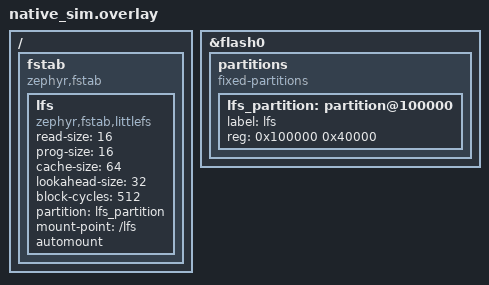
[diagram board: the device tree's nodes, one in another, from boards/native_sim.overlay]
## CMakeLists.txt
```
cmake_minimum_required(VERSION 3.20.0)

set(ZEPHYRDB_LOCAL_MODULE_DIR ${CMAKE_CURRENT_LIST_DIR}/modules/zephyrdb-local)
set(ZEPHYRDB_REPO_MODULE_DIR ${CMAKE_CURRENT_LIST_DIR}/../..)
if(EXISTS ${ZEPHYRDB_LOCAL_MODULE_DIR}/zephyr/module.yml OR
   EXISTS ${ZEPHYRDB_LOCAL_MODULE_DIR}/module.yml)
  list(APPEND EXTRA_ZEPHYR_MODULES ${ZEPHYRDB_LOCAL_MODULE_DIR})
elseif(EXISTS ${ZEPHYRDB_REPO_MODULE_DIR}/zephyr/module.yml OR
       EXISTS ${ZEPHYRDB_REPO_MODULE_DIR}/module.yml)
  list(APPEND EXTRA_ZEPHYR_MODULES ${ZEPHYRDB_REPO_MODULE_DIR})
else()
  message(FATAL_ERROR
    "shell_basic: zephyrdb module not found. Expected module.yml (or zephyr/module.yml) in one of: "
    "${ZEPHYRDB_LOCAL_MODULE_DIR} or ${ZEPHYRDB_REPO_MODULE_DIR}")
endif()

find_package(Zephyr REQUIRED HINTS $ENV{ZEPHYR_BASE})
project(zephyrdb_shell_basic)

target_sources(app PRIVATE src/main.c)
```

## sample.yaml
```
sample:
  name: ZephyrDB shell basic sample

common:
  tags:
    - zephyrdb
    - samples
    - shell
  integration_platforms:
    - native_sim

tests:
  zephyrdb.samples.shell_basic:
    harness: console
    harness_config:
      type: multi_line
      regex:
        - "shell_basic: KV selftest PASS"
        - "shell_basic: seeded kv/cfg, ts/temp, doc/sensors/s1"
        - "shell_basic: ZephyrDB shell ready"
    platform_allow:
      - native_sim
    timeout: 20
```

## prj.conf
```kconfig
CONFIG_CONSOLE=y
CONFIG_PRINTK=y
# The KV key index is sized by CONFIG_ZDB_KV_INDEX_MAX_ENTRIES and comes from
# this pool, as does every document field.
CONFIG_HEAP_MEM_POOL_SIZE=32768

CONFIG_SHELL=y
CONFIG_SHELL_BACKEND_SERIAL=y
# "zdb ts agg" and the f64 document commands print doubles.
CONFIG_CBPRINTF_FP_SUPPORT=y

CONFIG_FLASH=y
CONFIG_FLASH_MAP=y
CONFIG_FLASH_PAGE_LAYOUT=y
CONFIG_FLASH_SIMULATOR=y

CONFIG_FILE_SYSTEM=y
CONFIG_FILE_SYSTEM_LITTLEFS=y
CONFIG_FS_LITTLEFS_FMP_DEV=y
CONFIG_CRC=y

CONFIG_ZEPHYRDB=y
CONFIG_ZDB_SHELL=y
CONFIG_ZDB_STATS=y

CONFIG_ZDB_KV=y
CONFIG_ZDB_KV_BACKEND_ZMS=y
CONFIG_ZMS=y
CONFIG_NVS=n

CONFIG_ZDB_TS=y
CONFIG_ZDB_TS_BACKEND_LITTLEFS=y

CONFIG_ZDB_DOC=y
```

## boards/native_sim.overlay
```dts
/*
 * LittleFS partition and fstab automount for native_sim.
 *
 * The base native_sim DTS provides a 2 MB simulated flash with partitions
 * up to 0x100000.  This overlay adds a 256 KB LittleFS partition in the
 * remaining space and an fstab entry so the filesystem is mounted
 * automatically at boot.  The time-series and document models need it; KV
 * uses the stock storage_partition.
 */

&flash0 {
	partitions {
		compatible = "fixed-partitions";
		#address-cells = <1>;
		#size-cells = <1>;

		lfs_partition: partition@100000 {
			label = "lfs";
			reg = <0x100000 0x40000>;
		};
	};
};

/ {
	fstab {
		compatible = "zephyr,fstab";
		lfs: lfs {
			compatible = "zephyr,fstab,littlefs";
			read-size = <16>;
			prog-size = <16>;
			cache-size = <64>;
			lookahead-size = <32>;
			block-cycles = <512>;
			partition = <&lfs_partition>;
			mount-point = "/lfs";
			automount;
		};
	};
};
```

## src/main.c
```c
#include <zephyr/kernel.h>
#include <zephyr/sys/printk.h>
#include <zephyr/device.h>
#include <zephyr/drivers/flash.h>
#include <zephyr/kvss/zms.h>
#include <zephyr/storage/flash_map.h>

#include "zephyrdb.h"

static struct zms_fs g_zms;

static zdb_cfg_t g_cfg = {
	.kv_backend_fs = NULL,
	.lfs_mount_point = CONFIG_ZDB_LFS_MOUNT_POINT,
	.work_q = &k_sys_work_q,
};

ZDB_DEFINE_STATIC(g_db, g_cfg);

#define ZDB_ZMS_PARTITION storage_partition
#define ZDB_ZMS_PARTITION_DEVICE PARTITION_DEVICE(ZDB_ZMS_PARTITION)
#define ZDB_ZMS_PARTITION_OFFSET PARTITION_OFFSET(ZDB_ZMS_PARTITION)

static int shell_basic_init_zms(struct zms_fs *fs)
{
	struct flash_pages_info info;
	int rc;

	fs->flash_device = ZDB_ZMS_PARTITION_DEVICE;
	if (!device_is_ready(fs->flash_device)) {
		printk("shell_basic: storage device not ready\n");
		return -ENODEV;
	}

	fs->offset = ZDB_ZMS_PARTITION_OFFSET;
	rc = flash_get_page_info_by_offs(fs->flash_device, fs->offset, &info);
	if (rc != 0) {
		printk("shell_basic: flash page info failed rc=%d\n", rc);
		return rc;
	}

	fs->sector_size = info.size;
	fs->sector_count = 3U;

	rc = zms_mount(fs);
	if (rc != 0) {
		printk("shell_basic: zms mount failed rc=%d\n", rc);
		return rc;
	}

	return 0;
}

static int shell_basic_kv_selftest(zdb_t *db)
{
	zdb_kv_t kv;
	zdb_status_t rc;
	uint32_t write_value = 7U;
	uint32_t read_value = 0U;
	size_t out_len = 0U;

	rc = zdb_kv_open(db, "shell", &kv);
	if (rc != ZDB_OK) {
		printk("shell_basic: selftest kv_open rc=%d\n", (int)rc);
		return -EIO;
	}

	rc = zdb_kv_set(&kv, "smoke", &write_value, sizeof(write_value));
	if (rc != ZDB_OK) {
		printk("shell_basic: selftest kv_set rc=%d\n", (int)rc);
		(void)zdb_kv_close(&kv);
		return -EIO;
	}

	rc = zdb_kv_get(&kv, "smoke", &read_value, sizeof(read_value), &out_len);
	if ((rc != ZDB_OK) || (out_len != sizeof(read_value)) || (read_value != write_value)) {
		printk("shell_basic: selftest kv_get rc=%d len=%u val=%u\n", (int)rc,
		       (unsigned int)out_len, (unsigned int)read_value);
		(void)zdb_kv_close(&kv);
		return -EIO;
	}

	rc = zdb_kv_delete(&kv, "smoke");
	if (rc != ZDB_OK) {
		printk("shell_basic: selftest kv_delete rc=%d\n", (int)rc);
		(void)zdb_kv_close(&kv);
		return -EIO;
	}

	(void)zdb_kv_close(&kv);
	printk("shell_basic: KV selftest PASS\n");

	return 0;
}

/*
 * Seed one namespace, one stream, and one document so every command in the
 * tree has something to report the first time it is run.
 */
static void shell_basic_seed(zdb_t *db)
{
	static const zdb_ts_sample_i64_t samples[] = {
		{.ts_ms = 1000U, .value = 20},
		{.ts_ms = 1001U, .value = 21},
		{.ts_ms = 1002U, .value = 22},
	};
	zdb_kv_t kv;
	zdb_ts_t ts;
	zdb_doc_t doc;

	if (zdb_kv_open(db, "cfg", &kv) == ZDB_OK) {
		(void)zdb_kv_set_str(&kv, "name", "kitchen");
		(void)zdb_kv_set(&kv, "cal", "\x00\xff\x10", 3U);
		(void)zdb_kv_close(&kv);
	}

	if (zdb_ts_open(db, "temp", &ts) == ZDB_OK) {
		for (size_t i = 0U; i < ARRAY_SIZE(samples); i++) {
			(void)zdb_ts_append_i64(&ts, &samples[i]);
		}
		/* Closing writes out whatever is buffered. */
		(void)zdb_ts_close(&ts);
	}

	if (zdb_doc_create(db, "sensors", "s1", &doc) == ZDB_OK) {
		(void)zdb_doc_field_set_i64(&doc, "temp", 21);
		(void)zdb_doc_field_set_string(&doc, "label", "kitchen");
		(void)zdb_doc_field_set_bool(&doc, "active", true);
		(void)zdb_doc_save(&doc);
		(void)zdb_doc_close(&doc);
	}

	printk("shell_basic: seeded kv/cfg, ts/temp, doc/sensors/s1\n");
}

int main(void)
{
	zdb_status_t rc;
	int zms_rc;
	int selftest_rc;

	zms_rc = shell_basic_init_zms(&g_zms);
	if (zms_rc != 0) {
		return 1;
	}

	g_cfg.kv_backend_fs = &g_zms;

	rc = zdb_init(&g_db, &g_cfg);
	if (rc != ZDB_OK) {
		printk("shell_basic: zdb_init failed rc=%d\n", (int)rc);
		return 1;
	}

	selftest_rc = shell_basic_kv_selftest(&g_db);
	if (selftest_rc != 0) {
		return 1;
	}

	shell_basic_seed(&g_db);

	zdb_shell_register(&g_db);
	printk("shell_basic: ZephyrDB shell ready.\n");
	printk("shell_basic: try zdb info, zdb kv list cfg, zdb ts read temp, "
	       "zdb doc get sensors s1\n");

	while (1) {
		k_sleep(K_SECONDS(1));
	}

	return 0;
}
```
